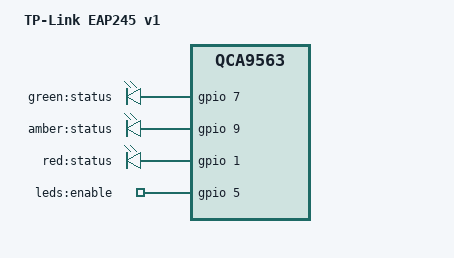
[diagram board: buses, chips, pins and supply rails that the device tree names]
// SPDX-License-Identifier: GPL-2.0-or-later OR MIT

#include "qca9563_tplink_eap2x5-1port.dtsi"

/ {
	compatible = "tplink,eap245-v1", "qca,qca9563";
	model = "TP-Link EAP245 v1";

	aliases {
		led-boot = &led_status_green;
		led-failsafe = &led_status_amber;
		led-running = &led_status_green;
		led-upgrade = &led_status_amber;
	};

	leds {
		compatible = "gpio-leds";

		led_status_green: status_green {
			label = "green:status";
			gpios = <&gpio 7 GPIO_ACTIVE_HIGH>;
			default-state = "on";
		};

		led_status_amber: status_amber {
			label = "amber:status";
			gpios = <&gpio 9 GPIO_ACTIVE_HIGH>;
		};

		led_status_red: status_red {
			label = "red:status";
			gpios = <&gpio 1 GPIO_ACTIVE_HIGH>;
		};
	};

	gpio-export {
		compatible = "gpio-export";
		led_enable {
			gpio-export,name = "leds:enable";
			gpio-export,output = <1>;
			gpios = <&gpio 5 GPIO_ACTIVE_HIGH>;
		};
	};
};
